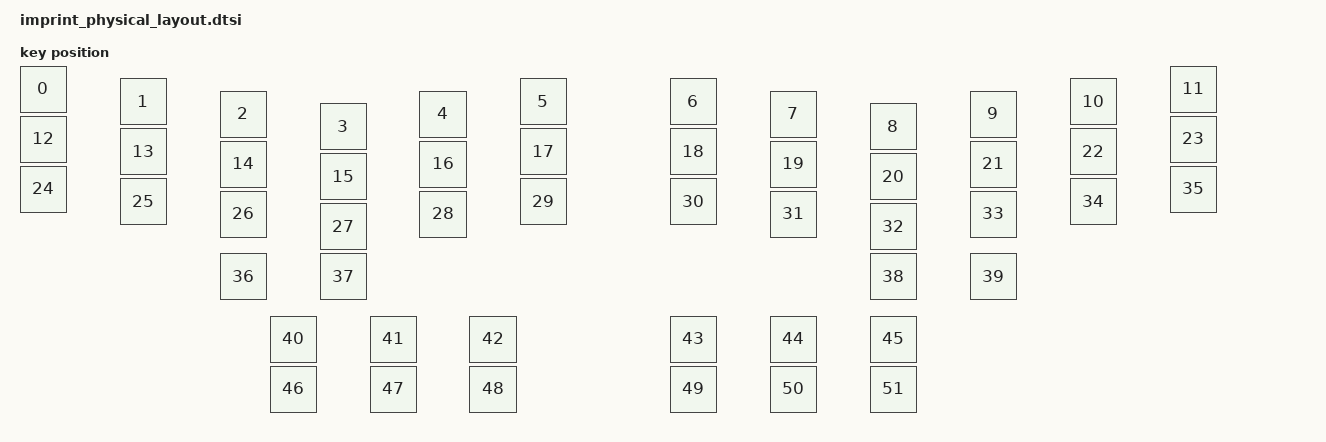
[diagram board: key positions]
#include <physical_layouts.dtsi>

/ {
    physical_layouts {
        compatible = "zmk,physical-layouts";

        imprint_letters_only_layout: imprint_letters_only_layout {
            display-name = "Letters Only";
            transform = <&imprint_letters_only>;

            keys = <
/* Left hand - top row (RC(4,x)): pinky to index */
&key_physical_attrs 100 100 0    0   0 0   0
&key_physical_attrs 100 100 200  25  0 200 25
&key_physical_attrs 100 100 400  50  0 400 50
&key_physical_attrs 100 100 600  75  0 600 75
&key_physical_attrs 100 100 800  50  0 800 50
&key_physical_attrs 100 100 1000 25  0 1000 25

/* Right hand - top row (RC(11,x)): index to pinky */
&key_physical_attrs 100 100 1300 25  0 1300 25
&key_physical_attrs 100 100 1500 50  0 1500 50
&key_physical_attrs 100 100 1700 75  0 1700 75
&key_physical_attrs 100 100 1900 50  0 1900 50
&key_physical_attrs 100 100 2100 25  0 2100 25
&key_physical_attrs 100 100 2300 0   0 2300 0

/* Left hand - middle row (RC(3,x)) */
&key_physical_attrs 100 100 0    100 0 0    100
&key_physical_attrs 100 100 200  125 0 200  125
&key_physical_attrs 100 100 400  150 0 400  150
&key_physical_attrs 100 100 600  175 0 600  175
&key_physical_attrs 100 100 800  150 0 800  150
&key_physical_attrs 100 100 1000 125 0 1000 125

/* Right hand - middle row (RC(10,x)) */
&key_physical_attrs 100 100 1300 125 0 1300 125
&key_physical_attrs 100 100 1500 150 0 1500 150
&key_physical_attrs 100 100 1700 175 0 1700 175
&key_physical_attrs 100 100 1900 150 0 1900 150
&key_physical_attrs 100 100 2100 125 0 2100 125
&key_physical_attrs 100 100 2300 100 0 2300 100

/* Left hand - bottom row (RC(2,x)) */
&key_physical_attrs 100 100 0    200 0 0    200
&key_physical_attrs 100 100 200  225 0 200  225
&key_physical_attrs 100 100 400  250 0 400  250
&key_physical_attrs 100 100 600  275 0 600  275
&key_physical_attrs 100 100 800  250 0 800  250
&key_physical_attrs 100 100 1000 225 0 1000 225

/* Right hand - bottom row (RC(9,x)) */
&key_physical_attrs 100 100 1300 225 0 1300 225
&key_physical_attrs 100 100 1500 250 0 1500 250
&key_physical_attrs 100 100 1700 275 0 1700 275
&key_physical_attrs 100 100 1900 250 0 1900 250
&key_physical_attrs 100 100 2100 225 0 2100 225
&key_physical_attrs 100 100 2300 200 0 2300 200

/* Light blue keys - partial bottom row */
/* Left: RC(1,3) RC(1,2) */
&key_physical_attrs 100 100 400  375 0 400  375
&key_physical_attrs 100 100 600  375 0 600  375

/* Right: RC(8,2) RC(8,3) */
&key_physical_attrs 100 100 1700 375 0 1700 375
&key_physical_attrs 100 100 1900 375 0 1900 375

/* Left thumb cluster - top row: RC(0,3) RC(0,2) RC(0,1) */
&key_physical_attrs 100 100 500  500 0 500  500
&key_physical_attrs 100 100 700  500 0 700  500
&key_physical_attrs 100 100 900  500 0 900  500

/* Right thumb cluster - top row: RC(7,1) RC(7,2) RC(7,3) */
&key_physical_attrs 100 100 1300 500 0 1300 500
&key_physical_attrs 100 100 1500 500 0 1500 500
&key_physical_attrs 100 100 1700 500 0 1700 500

/* Left thumb cluster - bottom row: RC(0,7) RC(0,6) RC(0,5) */
&key_physical_attrs 100 100 500  600 0 500  600
&key_physical_attrs 100 100 700  600 0 700  600
&key_physical_attrs 100 100 900  600 0 900  600

/* Right thumb cluster - bottom row: RC(7,5) RC(7,6) RC(7,7) */
&key_physical_attrs 100 100 1300 600 0 1300 600
&key_physical_attrs 100 100 1500 600 0 1500 600
&key_physical_attrs 100 100 1700 600 0 1700 600
            >;
        };
    };
};
